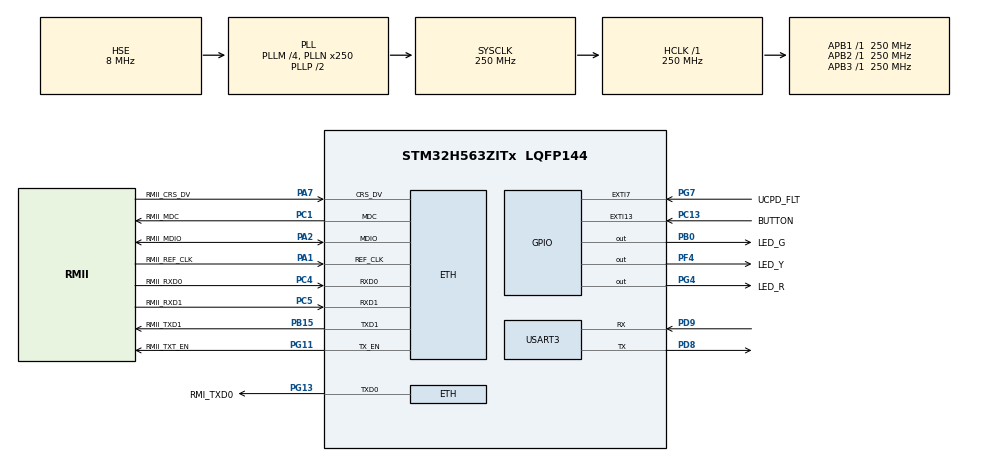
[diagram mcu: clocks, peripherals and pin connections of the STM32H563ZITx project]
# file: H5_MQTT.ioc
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BOOTPATH.BootPathName=LEGACY
BOOTPATH.UserSelectedBootPath=LEGACY
CORTEX_M33_NS.userName=CORTEX_M33
ETH.MediaInterface=HAL_ETH_RMII_MODE
Mcu.Family=STM32H5
Mcu.Name=STM32H563ZITx
Mcu.Package=LQFP144
NETXDUO.ETH_ON=1
NETXDUO.LAN_8742=1
NETXDUO.NX_APP_MEM_POOL_SIZE=8*1024
NUCLEO-H563ZI.LD1=false
NUCLEO-H563ZI.LD2=false
NUCLEO-H563ZI.LD3=false
NUCLEO-H563ZI.VCP=true
NVIC.ETH_IRQn=true\:0\:0\:false\:false\:true\:false\:true\:true\:true
NVIC.EXTI13_IRQn=true\:0\:0\:false\:false\:true\:false\:true\:true\:true
NVIC.PriorityGroup=NVIC_PRIORITYGROUP_4
NVIC.TIM6_IRQn=true\:15\:0\:false\:false\:true\:false\:false\:true\:true
NVIC.TimeBase=TIM6_IRQn
NVIC.TimeBaseIP=TIM6
NetXDuo.BSP.number=1
NetXDuo0.BSP.STBoard=false
NetXDuo0.BSP.api=BSP_COMPONENT_DRIVER
NetXDuo0.BSP.component=lan8742
NetXDuo0.BSP.instance=lan8742
NetXDuo0.BSP.name=LAN_Component
NetXDuo0.BSP.semaphore=SEMA_lan8742
NetXDuo0.BSP.solution=lan8742
PA1.GPIO_Label=RMII_REF_CLK
PA1.GPIO_Mode=GPIO_MODE_AF_PP
PA1.GPIO_PuPd=GPIO_NOPULL
PA1.GPIO_Speed=GPIO_SPEED_FREQ_LOW
PA1.Mode=RMII
PA1.Signal=ETH_REF_CLK
PA11.GPIO_Label=USB_FS_N
PA11.Signal=USB_DM
PA12.GPIO_Label=USB_FS_P
PA12.Signal=USB_DP
PA13(JTMS/SWDIO).GPIO_Label=SWDIO
PA13(JTMS/SWDIO).Signal=DEBUG_JTMS-SWDIO
PA14(JTCK/SWCLK).GPIO_Label=SWCLK
PA14(JTCK/SWCLK).Signal=DEBUG_JTCK-SWCLK
PA15(JTDI).GPIO_Label=T_JTDI
PA15(JTDI).Signal=DEBUG_JTDI
PA2.GPIO_Label=RMII_MDIO
PA2.GPIO_Mode=GPIO_MODE_AF_PP
PA2.GPIO_PuPd=GPIO_NOPULL
PA2.GPIO_Speed=GPIO_SPEED_FREQ_LOW
PA2.Mode=RMII
PA2.Signal=ETH_MDIO
PA4.GPIO_Label=VBUS_SENSE
PA4.Signal=ADCx_INP18
PA7.GPIO_Label=RMII_CRS_DV
PA7.GPIO_Mode=GPIO_MODE_AF_PP
PA7.GPIO_PuPd=GPIO_NOPULL
PA7.GPIO_Speed=GPIO_SPEED_FREQ_LOW
PA7.Mode=RMII
PA7.Signal=ETH_CRS_DV
PA9.GPIO_Label=UCDP_DBn
PA9.Signal=UCPD1_DB1
PB0.GPIO_Label=LED_G
PB0.Signal=GPIO_Output
PB13.GPIO_Label=UCPD_CC1
PB13.Signal=UCPD1_CC1
PB14.GPIO_Label=UCPD_CC2
PB14.Signal=UCPD1_CC2
PB15.GPIO_Label=RMII_TXD1
PB15.GPIO_Mode=GPIO_MODE_AF_PP
PB15.GPIO_PuPd=GPIO_NOPULL
PB15.GPIO_Speed=GPIO_SPEED_FREQ_LOW
PB15.Mode=RMII
PB15.Signal=ETH_TXD1
PB3(JTDO/TRACESWO).GPIO_Label=SWO
PB3(JTDO/TRACESWO).Signal=DEBUG_JTDO-SWO
PB6.GPIO_Label=ARD_D1_TX
PB6.Signal=LPUART1_TX
PB7.GPIO_Label=ARD_D0_RX
PB7.Signal=LPUART1_RX
PC1.GPIO_Label=RMII_MDC
PC1.GPIO_Mode=GPIO_MODE_AF_PP
PC1.GPIO_PuPd=GPIO_NOPULL
PC1.GPIO_Speed=GPIO_SPEED_FREQ_LOW
PC1.Mode=RMII
PC1.Signal=ETH_MDC
PC13.GPIO_Label=BUTTON
PC13.Signal=GPXTI13
PC14-OSC32_IN(OSC32_IN).Mode=LSE-External-Oscillator
PC14-OSC32_IN(OSC32_IN).Signal=RCC_OSC32_IN
PC15-OSC32_OUT(OSC32_OUT).Mode=LSE-External-Oscillator
PC15-OSC32_OUT(OSC32_OUT).Signal=RCC_OSC32_OUT
PC4.GPIO_Label=RMII_RXD0
PC4.GPIO_Mode=GPIO_MODE_AF_PP
PC4.GPIO_PuPd=GPIO_NOPULL
PC4.GPIO_Speed=GPIO_SPEED_FREQ_LOW
PC4.Mode=RMII
PC4.Signal=ETH_RXD0
PC5.GPIO_Label=RMII_RXD1
PC5.GPIO_Mode=GPIO_MODE_AF_PP
PC5.GPIO_PuPd=GPIO_NOPULL
PC5.GPIO_Speed=GPIO_SPEED_FREQ_LOW
PC5.Mode=RMII
PC5.Signal=ETH_RXD1
PD8.Mode=Asynchronous
PD8.Signal=USART3_TX
PD9.Mode=Asynchronous
PD9.Signal=USART3_RX
PE2.GPIO_Label=TRACE_CK
PE2.Signal=DEBUG_TRACECLK
PE3.GPIO_Label=TRACE_D0
PE3.Signal=DEBUG_TRACED0
PE4.GPIO_Label=TRACE_D1
PE4.Signal=DEBUG_TRACED1
PE5.GPIO_Label=TRACE_D2
PE5.Signal=DEBUG_TRACED2
PE6.GPIO_Label=TRACE_D3
PE6.Signal=DEBUG_TRACED3
PF4.GPIO_Label=LED_Y
PF4.Signal=GPIO_Output
PG11.GPIO_Label=RMII_TXT_EN
PG11.GPIO_Mode=GPIO_MODE_AF_PP
PG11.GPIO_PuPd=GPIO_NOPULL
PG11.GPIO_Speed=GPIO_SPEED_FREQ_LOW
PG11.Mode=RMII
PG11.Signal=ETH_TX_EN
PG13.GPIO_Label=RMI_TXD0
PG13.GPIO_Mode=GPIO_MODE_AF_PP
PG13.GPIO_PuPd=GPIO_NOPULL
PG13.GPIO_Speed=GPIO_SPEED_FREQ_LOW
PG13.Mode=RMII
PG13.Signal=ETH_TXD0
PG4.GPIO_Label=LED_R
PG4.Signal=GPIO_Output
PG7.GPIO_Label=UCPD_FLT
PG7.Signal=GPXTI7
PH0-OSC_IN(PH0).GPIO_Label=STLK_MCO
PH0-OSC_IN(PH0).Mode=HSE-External-Clock-Source
PH0-OSC_IN(PH0).Signal=RCC_OSC_IN
ProjectManager.HeapSize=0x400
ProjectManager.StackSize=0x800
ProjectManager.TargetToolchain=Makefile
RCC.ADCFreq_Value=250000000
RCC.AHBFreq_Value=250000000
RCC.APB1Freq_Value=250000000
RCC.APB1TimFreq_Value=250000000
RCC.APB2Freq_Value=250000000
RCC.APB2TimFreq_Value=250000000
RCC.APB3Freq_Value=250000000
RCC.CSI_VALUE=4000000
RCC.CortexFreq_Value=250000000
RCC.EPOD_VALUE=8000000
RCC.HCLKFreq_Value=250000000
RCC.HSE_VALUE=8000000
RCC.HSI48_VALUE=48000000
RCC.HSIDiv=RCC_HSI_DIV1
RCC.HSI_VALUE=64000000
RCC.LSIRC_VALUE=32000
RCC.PLLM=4
RCC.PLLN=250
RCC.PLLSourceVirtual=RCC_PLL1_SOURCE_HSE
RCC.SYSCLKFreq_VALUE=250000000
RCC.SYSCLKSource=RCC_SYSCLKSOURCE_PLLCLK
RCC.USBFreq_Value=48000000
RCC.VCOOutputFreq_Value=500000000
SH.ADCx_INP18.0=ADC1_INP18
THREADX.TX_APP_MEM_POOL_SIZE=16*1024
VP_BOOTPATH_VS_BOOTPATH.Mode=BP_Activate
VP_CORTEX_M33_NS_VS_Hclk.Mode=Hclk_Mode
VP_ICACHE_VS_ICACHE.Mode=DirectMappedCache
VP_MEMORYMAP_VS_MEMORYMAP.Mode=CurAppReg
VP_NETXDUO_VS_AddonsOoDHCP.Mode=Addons_DHCP_Client
VP_NETXDUO_VS_AddonsOoDNS.Mode=Addons_DNS
VP_NETXDUO_VS_AddonsOoMQTT.Mode=Addons_MQTT
VP_NETXDUO_VS_EthernetOoPhyOoInterface.Mode=LAN8742_Phy_Interface
VP_NETXDUO_VS_NXOoCore.Mode=NX_Core
VP_NETXDUO_VS_NetworkOoInterface.Mode=Ethernet_Interface
VP_NUCLEO-H563ZI_VS_BSP_COMMON.Mode=COMMON
VP_PWR_VS_DBSignals.Mode=DisableDeadBatterySignals
VP_PWR_VS_LPOM.Mode=PowerOptimisation
VP_PWR_VS_SECSignals.Mode=Security/Privilege
VP_SYS_VS_tim6.Mode=TIM6
VP_THREADX_VS_RTOSJjThreadXJjCoreJjDefault.Mode=Core_Default
VP_THREADX_VS_RTOSJjThreadXJjTraceX_SupportJjDefault.Mode=TraceX_Support_Default
board=NUCLEO-H563ZI

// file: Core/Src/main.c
/* USER CODE BEGIN Header */
/**
  ******************************************************************************
  * @file           : main.c
  * @brief          : Main program body
  ******************************************************************************
  * @attention
  *
  * Copyright (c) 2024 STMicroelectronics.
  * All rights reserved.
  *
  * This software is licensed under terms that can be found in the LICENSE file
  * in the root directory of this software component.
  * If no LICENSE file comes with this software, it is provided AS-IS.
  *
  ******************************************************************************
  */
/* USER CODE END Header */
#include "app_threadx.h"
#include "main.h"
#include "string.h"

ETH_TxPacketConfigTypeDef TxConfig;
ETH_DMADescTypeDef  DMARxDscrTab[ETH_RX_DESC_CNT]; /* Ethernet Rx DMA Descriptors */
ETH_DMADescTypeDef  DMATxDscrTab[ETH_TX_DESC_CNT]; /* Ethernet Tx DMA Descriptors */

COM_InitTypeDef BspCOMInit;

ETH_HandleTypeDef heth;

void SystemClock_Config(void);
static void MX_GPIO_Init(void);
static void MX_ETH_Init(void);
static void MX_ICACHE_Init(void);

int main(void)
{

  /* MCU Configuration--------------------------------------------------------*/

  /* Reset of all peripherals, Initializes the Flash interface and the Systick. */
  HAL_Init();

  /* Configure the system clock */
  SystemClock_Config();

  /* Initialize all configured peripherals */
  MX_GPIO_Init();
  MX_ETH_Init();
  MX_ICACHE_Init();
  /* USER CODE BEGIN 2 */

  /* Initialize COM1 port (115200, 8 bits (7-bit data + 1 stop bit), no parity */
  BspCOMInit.BaudRate   = 115200;
  BspCOMInit.WordLength = COM_WORDLENGTH_8B;
  BspCOMInit.StopBits   = COM_STOPBITS_1;
  BspCOMInit.Parity     = COM_PARITY_NONE;
  BspCOMInit.HwFlowCtl  = COM_HWCONTROL_NONE;
  if (BSP_COM_Init(COM1, &BspCOMInit) != BSP_ERROR_NONE)
  {
    Error_Handler();
  }
  /* USER CODE END 2 */

  MX_ThreadX_Init();

  /* We should never get here as control is now taken by the scheduler */

  /* Infinite loop */
  while (1)
  {

  }
}

void SystemClock_Config(void)
{
  RCC_OscInitTypeDef RCC_OscInitStruct = {0};
  RCC_ClkInitTypeDef RCC_ClkInitStruct = {0};

  /** Configure the main internal regulator output voltage
  */
  __HAL_PWR_VOLTAGESCALING_CONFIG(PWR_REGULATOR_VOLTAGE_SCALE0);

  while(!__HAL_PWR_GET_FLAG(PWR_FLAG_VOSRDY)) {}

  /** Initializes the RCC Oscillators according to the specified parameters
  * in the RCC_OscInitTypeDef structure.
  */
  RCC_OscInitStruct.OscillatorType = RCC_OSCILLATORTYPE_HSE;
  RCC_OscInitStruct.HSEState = RCC_HSE_BYPASS;
  RCC_OscInitStruct.PLL.PLLState = RCC_PLL_ON;
  RCC_OscInitStruct.PLL.PLLSource = RCC_PLL1_SOURCE_HSE;
  RCC_OscInitStruct.PLL.PLLM = 4;
  RCC_OscInitStruct.PLL.PLLN = 250;
  RCC_OscInitStruct.PLL.PLLP = 2;
  RCC_OscInitStruct.PLL.PLLQ = 2;
  RCC_OscInitStruct.PLL.PLLR = 2;
  RCC_OscInitStruct.PLL.PLLRGE = RCC_PLL1_VCIRANGE_1;
  RCC_OscInitStruct.PLL.PLLVCOSEL = RCC_PLL1_VCORANGE_WIDE;
  RCC_OscInitStruct.PLL.PLLFRACN = 0;
  if (HAL_RCC_OscConfig(&RCC_OscInitStruct) != HAL_OK)
  {
    Error_Handler();
  }

  /** Initializes the CPU, AHB and APB buses clocks
  */
  RCC_ClkInitStruct.ClockType = RCC_CLOCKTYPE_HCLK|RCC_CLOCKTYPE_SYSCLK
                              |RCC_CLOCKTYPE_PCLK1|RCC_CLOCKTYPE_PCLK2
                              |RCC_CLOCKTYPE_PCLK3;
  RCC_ClkInitStruct.SYSCLKSource = RCC_SYSCLKSOURCE_PLLCLK;
  RCC_ClkInitStruct.AHBCLKDivider = RCC_SYSCLK_DIV1;
  RCC_ClkInitStruct.APB1CLKDivider = RCC_HCLK_DIV1;
  RCC_ClkInitStruct.APB2CLKDivider = RCC_HCLK_DIV1;
  RCC_ClkInitStruct.APB3CLKDivider = RCC_HCLK_DIV1;

  if (HAL_RCC_ClockConfig(&RCC_ClkInitStruct, FLASH_LATENCY_5) != HAL_OK)
  {
    Error_Handler();
  }
}

static void MX_ETH_Init(void)
{

   static uint8_t MACAddr[6];

  heth.Instance = ETH;
  MACAddr[0] = 0x00;
  MACAddr[1] = 0x80;
  MACAddr[2] = 0xE1;
  MACAddr[3] = 0x00;
  MACAddr[4] = 0x00;
  MACAddr[5] = 0x00;
  heth.Init.MACAddr = &MACAddr[0];
  heth.Init.MediaInterface = HAL_ETH_RMII_MODE;
  heth.Init.TxDesc = DMATxDscrTab;
  heth.Init.RxDesc = DMARxDscrTab;
  heth.Init.RxBuffLen = 1524;

  if (HAL_ETH_Init(&heth) != HAL_OK)
  {
    Error_Handler();
  }

  memset(&TxConfig, 0 , sizeof(ETH_TxPacketConfigTypeDef));
  TxConfig.Attributes = ETH_TX_PACKETS_FEATURES_CSUM | ETH_TX_PACKETS_FEATURES_CRCPAD;
  TxConfig.ChecksumCtrl = ETH_CHECKSUM_IPHDR_PAYLOAD_INSERT_PHDR_CALC;
  TxConfig.CRCPadCtrl = ETH_CRC_PAD_INSERT;

}

static void MX_ICACHE_Init(void)
{

  /** Enable instruction cache in 1-way (direct mapped cache)
  */
  if (HAL_ICACHE_ConfigAssociativityMode(ICACHE_1WAY) != HAL_OK)
  {
    Error_Handler();
  }
  if (HAL_ICACHE_Enable() != HAL_OK)
  {
    Error_Handler();
  }

}

static void MX_GPIO_Init(void)
{
  GPIO_InitTypeDef GPIO_InitStruct = {0};

  /* GPIO Ports Clock Enable */
  __HAL_RCC_GPIOE_CLK_ENABLE();
  __HAL_RCC_GPIOC_CLK_ENABLE();
  __HAL_RCC_GPIOF_CLK_ENABLE();
  __HAL_RCC_GPIOH_CLK_ENABLE();
  __HAL_RCC_GPIOA_CLK_ENABLE();
  __HAL_RCC_GPIOB_CLK_ENABLE();
  __HAL_RCC_GPIOG_CLK_ENABLE();

  /*Configure GPIO pin Output Level */
  HAL_GPIO_WritePin(LED_Y_GPIO_Port, LED_Y_Pin, GPIO_PIN_RESET);

  /*Configure GPIO pin Output Level */
  HAL_GPIO_WritePin(LED_G_GPIO_Port, LED_G_Pin, GPIO_PIN_RESET);

  /*Configure GPIO pin Output Level */
  HAL_GPIO_WritePin(LED_R_GPIO_Port, LED_R_Pin, GPIO_PIN_RESET);

  /*Configure GPIO pin : BUTTON_Pin */
  GPIO_InitStruct.Pin = BUTTON_Pin;
  GPIO_InitStruct.Mode = GPIO_MODE_IT_RISING;
  GPIO_InitStruct.Pull = GPIO_NOPULL;
  HAL_GPIO_Init(BUTTON_GPIO_Port, &GPIO_InitStruct);

  /*Configure GPIO pin : LED_Y_Pin */
  GPIO_InitStruct.Pin = LED_Y_Pin;
  GPIO_InitStruct.Mode = GPIO_MODE_OUTPUT_PP;
  GPIO_InitStruct.Pull = GPIO_NOPULL;
  GPIO_InitStruct.Speed = GPIO_SPEED_FREQ_LOW;
  HAL_GPIO_Init(LED_Y_GPIO_Port, &GPIO_InitStruct);

  /*Configure GPIO pin : VBUS_SENSE_Pin */
  GPIO_InitStruct.Pin = VBUS_SENSE_Pin;
  GPIO_InitStruct.Mode = GPIO_MODE_ANALOG;
  GPIO_InitStruct.Pull = GPIO_NOPULL;
  HAL_GPIO_Init(VBUS_SENSE_GPIO_Port, &GPIO_InitStruct);

  /*Configure GPIO pin : LED_G_Pin */
  GPIO_InitStruct.Pin = LED_G_Pin;
  GPIO_InitStruct.Mode = GPIO_MODE_OUTPUT_PP;
  GPIO_InitStruct.Pull = GPIO_NOPULL;
  GPIO_InitStruct.Speed = GPIO_SPEED_FREQ_LOW;
  HAL_GPIO_Init(LED_G_GPIO_Port, &GPIO_InitStruct);

  /*Configure GPIO pins : UCPD_CC1_Pin UCPD_CC2_Pin */
  GPIO_InitStruct.Pin = UCPD_CC1_Pin|UCPD_CC2_Pin;
  GPIO_InitStruct.Mode = GPIO_MODE_ANALOG;
  GPIO_InitStruct.Pull = GPIO_NOPULL;
  HAL_GPIO_Init(GPIOB, &GPIO_InitStruct);

  /*Configure GPIO pin : LED_R_Pin */
  GPIO_InitStruct.Pin = LED_R_Pin;
  GPIO_InitStruct.Mode = GPIO_MODE_OUTPUT_PP;
  GPIO_InitStruct.Pull = GPIO_NOPULL;
  GPIO_InitStruct.Speed = GPIO_SPEED_FREQ_LOW;
  HAL_GPIO_Init(LED_R_GPIO_Port, &GPIO_InitStruct);

  /*Configure GPIO pin : UCPD_FLT_Pin */
  GPIO_InitStruct.Pin = UCPD_FLT_Pin;
  GPIO_InitStruct.Mode = GPIO_MODE_IT_RISING;
  GPIO_InitStruct.Pull = GPIO_NOPULL;
  HAL_GPIO_Init(UCPD_FLT_GPIO_Port, &GPIO_InitStruct);

  /*Configure GPIO pins : USB_FS_N_Pin USB_FS_P_Pin */
  GPIO_InitStruct.Pin = USB_FS_N_Pin|USB_FS_P_Pin;
  GPIO_InitStruct.Mode = GPIO_MODE_AF_PP;
  GPIO_InitStruct.Pull = GPIO_NOPULL;
  GPIO_InitStruct.Speed = GPIO_SPEED_FREQ_LOW;
  GPIO_InitStruct.Alternate = GPIO_AF10_USB;
  HAL_GPIO_Init(GPIOA, &GPIO_InitStruct);

  /*Configure GPIO pins : ARD_D1_TX_Pin ARD_D0_RX_Pin */
  GPIO_InitStruct.Pin = ARD_D1_TX_Pin|ARD_D0_RX_Pin;
  GPIO_InitStruct.Mode = GPIO_MODE_AF_PP;
  GPIO_InitStruct.Pull = GPIO_NOPULL;
  GPIO_InitStruct.Speed = GPIO_SPEED_FREQ_LOW;
  GPIO_InitStruct.Alternate = GPIO_AF8_LPUART1;
  HAL_GPIO_Init(GPIOB, &GPIO_InitStruct);

  /* EXTI interrupt init*/
  HAL_NVIC_SetPriority(EXTI13_IRQn, 0, 0);
  HAL_NVIC_EnableIRQ(EXTI13_IRQn);

}

void HAL_TIM_PeriodElapsedCallback(TIM_HandleTypeDef *htim)
{
  if (htim->Instance == TIM6) {
    HAL_IncTick();
  }
}

void Error_Handler(void)
{
  /* USER CODE BEGIN Error_Handler_Debug */
  /* User can add his own implementation to report the HAL error return state */
  __disable_irq();
  HAL_GPIO_WritePin(LED_R_GPIO_Port, LED_R_Pin, GPIO_PIN_SET);
  while (1)
  {
  }
  /* USER CODE END Error_Handler_Debug */
}
